# RN821X_RN721X_SOC_D register map
File version: v1.0.6
CPU: CM0 r0p0, little endian, no MPU, no FPU, 3 interrupt priority bits
Registers are 32-bit, read-write, reset 0x0 unless marked. A register's access mark holds for its fields unless they carry their own. Offsets are from the block's base; [hi:lo] are bit positions; {n}, {i} and the like mark numbered series; 'fields as' and 'values as' point back to an identical list.

## KBI — key detection
Base 0x40028000
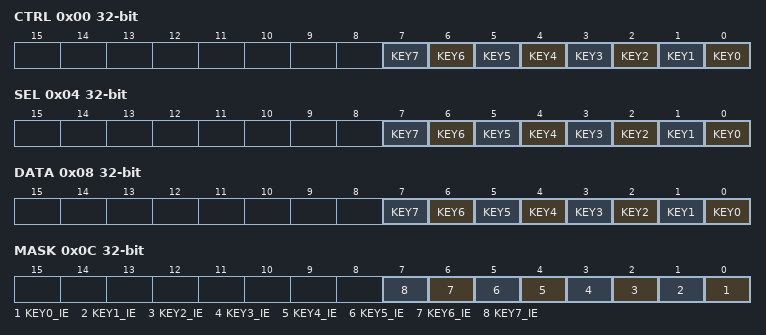
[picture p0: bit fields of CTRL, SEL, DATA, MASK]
0x00 CTRL — KBI control register
  [n] KEY{n} (n=0..7) — KBI KEY{n} enable/disable bit
    1=EN (KBI KEY{n} enable); 0=DIS (KBI KEY{n} disable)
0x04 SEL — KBI trigger mode select register
  [all] fields
    0=PE (KBI select posedge sampling); 1=NE (KBI select negedge sampling)
  [n] KEY{n} (n=0..7) — KBI KEY{n} posedge/negedge selection bit
0x08 DATA — KBI data register
  [all] fields
    1=PD (KEY pressed); 0=NUL (KEY not be pressed)
  [n] KEY{n} write-1-clears (n=0..7) — KBI KEY{n} data bit indicate key pressed or not
0x0C MASK — KBI interrupt mask register
  [n] KEY{n}_IE (n=0..7) — KBI KEY{n} interrupt enable/disable bit

## NVM — no voltage module
Base 0x40040000
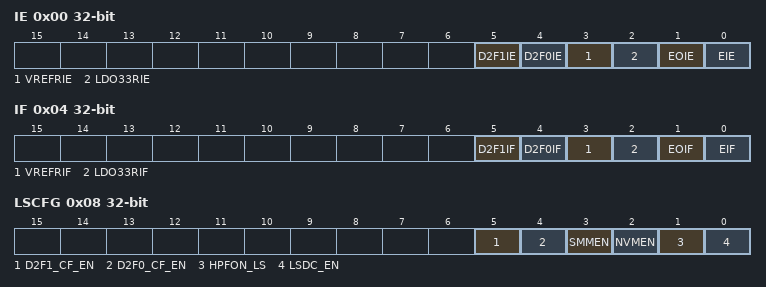
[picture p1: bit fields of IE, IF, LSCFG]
0x00 IE — interrupt enables
  [5] D2F1IE — d2f1 pulse interrupt enable
    0=DIS (do not generate interrupt when d2f1 pulse is output); 1=EN (generate interrupt when d2f1 pulse is output)
  [4] D2F0IE — d2f0 pulse interrupt enable
    0=DIS (do not generate interrupt when d2f0 pulse is output); 1=EN (generate interrupt when d2f0 pulse is output)
  [3] VREFRIE — VREF reset interrupt enable
    0=DIS (do not generate interrupt when VREF reset found); 1=EN (generate interrupt when VREF reset found)
  [2] LDO33RIE — LDO33 reset interrupt enable
    0=DIS (do not generate interrupt when reset found in LDO33 power domain); 1=EN (generate interrupt when reset found in LDO33 power domain)
  [1] EOIE — NV end and overflow interrupt enable
    0=DIS (do not generate interrupt when NV computation ends and NV value beyond threshold); 1=EN (generate interrupt when NV computation ends and NV value beyond threshold)
  [0] EIE — NV end interrupt enable
    0=DIS (do not generate interrupt when NV computation ends); 1=EN (generate interrupt when NV computation ends)
0x04 IF — interrupt flag
  [5] D2F1IF — d2f1 impulse interrupt flag
    0=NULL (no pending event of d2f1 impulse); 1=OCC (pending event of d2f1 impulse interrupt flag)
  [4] D2F0IF — d2f0 impulse interrupt flag
    0=NULL (no pending event of d2f0 impulse); 1=OCC (pending event of d2f0 impulse interrupt flag)
  [3] VREFRIF — VREF reset interrupt flag
    0=NULL (no pending event of VREF domain reset); 1=OCC (pending event of VREF domain reset found)
  [2] LDO33RIF — LDO33 reset interrupt flag
    0=NULL (no pending event of LDO33 power domain reset); 1=OCC (pending event of LDO33 power domain reset found)
  [1] EOIF — NV end and overflow interrupt flag
    0=NULL (no pending event of NV computation ends and NV value beyond threshold); 1=OCC (pending event of NV computation ends and NV value beyond threshold found)
  [0] EIF — NV end interrupt flag
    values as EOIF
0x08 LSCFG — NV config
  [5] D2F1_CF_EN — SMM enable
    0=DIS (D2F1 pulse not output to io); 1=EN (D2F1 pulse output to io)
  [4] D2F0_CF_EN — SMM enable
    0=DIS; 1=EN
  [3] SMMEN — SMM enable
    0=DIS (RMS updated every 20ms); 1=EN (RMS updated every 80ms)
  [2] NVMEN — module enable
    0=DIS (disabled); 1=EN (enabled)
  [1] HPFON_LS — high pass filter enable
    0=DIS (disabled); 1=EN (enabled)
  [0] LSDC_EN — automatic DC offset calibration enable
    0=DIS (disabled); 1=EN (enabled)
0x0C LSDCOS — NV measurement DC offset.
  [23:0] LSDCOS
0x10 LSTHO — NV measurement threshold
  [23:0] LSTHO
0x14 LSRMS ro — IA cyclic updated NV measurement RMS
  [23:0] LSRMS
0x18 LSRMS1 ro — IA RMS_L1 will not change after calculation
  [23:0] LSRMS1
0x20 HFCONST — HF const value
  [15:0] HFCONST
0x24 D2FP0 — D2F power 0 vaule
  [23:0] D2FP0
0x28 D2FP1 — D2F power 1 vaule
  [23:0] D2FP1

## SPI0 — synchronous peripheral interface
Base 0x40020000
Same registers: SPI1 0x40050000
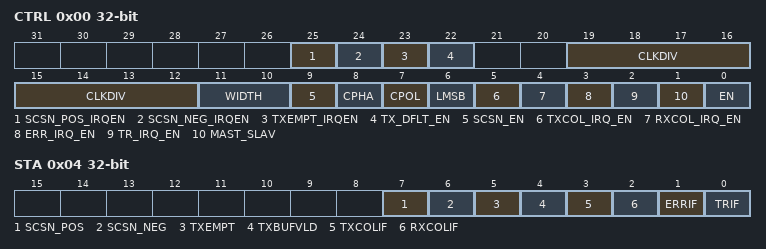
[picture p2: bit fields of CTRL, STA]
0x00 CTRL — SPI control register
  [25] SCSN_POS_IRQEN — CSN POS interrupt
  [24] SCSN_NEG_IRQEN — CSN NEG interrupt
  [23] TXEMPT_IRQEN — transmit empty interrupt
  [22] TX_DFLT_EN — transmit data when TX buffer empty
    1=DFLT (transmit SPI_TXDFLT reg data when transmit buffer empty); 0=LAST (transmit last time reg data of SPI_TXDATA when transmit buffer empty)
  [19:12] CLKDIV — clock divisor for SCK.frequency of SCK is (frequency of system clock)/(2*(CLKDIV+1))
  [11:10] WIDTH — data width selection
    0=8BIT (select data width as 8 bit); 1=16BIT (select data width as 16 bit); 2=32BIT (select data width as 32 bit)
  [9] SCSN_EN — SCSN error detection enable.applicable in master mode
  [8] CPHA — clock phase selection
    0=SAMP (leading edge sampling data, trailing edge build data); 1=BUILD (leading edge build data, trailing edge sampling data)
  [7] CPOL — clock polarity selection
    0=EL (select low level for 'SCK' empty status); 1=EH (select high level for 'SCK' empty status)
  [6] LMSB — LSB or MSB selection
    0=MSB (MSB transmitted first); 1=LSB (LSB transmitted first)
  [5] TXCOL_IRQ_EN — transmit data collision interrupt enable
  [4] RXCOL_IRQ_EN — receive data collision interrupt enable
  [3] ERR_IRQ_EN — SCSN error interrupt enable
  [2] TR_IRQ_EN — transmit interrupt enable
  [1] MAST_SLAV — master slave selection
    1=M (select as master device); 0=S (select as slave device)
  [0] EN — module enable
0x04 STA — SPI status register
  [7] SCSN_POS — CSN negedge flag
  [6] SCSN_NEG — CSN posedge flag
  [5] TXEMPT — transmit buffer empty conflict flag (buffer empty but need to transmit)
  [4] TXBUFVLD — transmit buffer not empty flag
  [3] TXCOLIF write-1-clears — transmit data overflow interrupt flag
  [2] RXCOLIF write-1-clears — receive data overflow interrupt flag
  [1] ERRIF write-1-clears — SCSN error interrupt flag
  [0] TRIF write-1-clears — transmit interrupt flag
0x08 TX — SPI transmit data register
  [31:0] TX — transmit data bits
0x0C RX ro — SPI receive data register
  [31:0] RX — receive data bits
0x10 TXDFLT — SPI tx default data register
  [31:0] TXDFLT — transmit default data bits

## UART0 — UART tranceiver
Base 0x40000000
Same registers: UART1 0x40004000, UART2 0x40008000, UART3 0x4000C000, UART4 0x40018000, UART5 0x4001C000
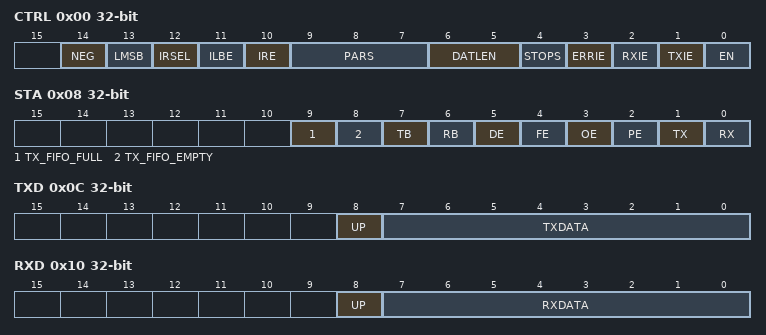
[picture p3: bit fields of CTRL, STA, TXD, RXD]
0x00 CTRL — UART control register
  [14] NEG — UART transfer polarity selection bit
    0=P (positive polarity (default driving voltage is high)); 1=N (negative polarity (default driving voltage is low))
  [13] LMSB — LSB/MSB transfer mode selection
    0=L (LSB first transfer mode); 1=M (MSB first transfer mode)
  [12] IRSEL — infra-red modulation polarity selection bit
    0=P (positive polarity. default driving voltage is high); 1=N (negative polarity. default driving voltage is low)
  [11] ILBE — inner loopback enable bit
  [10] IRE — infra-red modulation enable bit
  [9:7] PARS — parity type selection bits
    0=NUL (parity type select no parity); 1=ODD (parity type select odd parity); 2=EVEN (parity type select even parity); 3=parity type select stick_zero parity; 4=parity type select stick one parity; 5=USER (parity type select user_defined parity)
  [6:5] DATLEN — data length of frame format Configuration bits
    {v}=select {v+5} bits of data field (v=0..3)
  [4] STOPS — stop bits width selection bit
    1=2BIT (stop bit_width select as 2 bit); 0=1BIT (stop bit_width select as 1 bit)
  [3] ERRIE — error interrupt enable bit
  [2] RXIE — receive interrupt enable bit
  [1] TXIE — transmit interrupt enable bit
  [0] EN — UART module enable bit
0x04 BAUD — UART baud rate configuration register
  [11:0] CLKDIV — baud rate configuration bits
0x08 STA — UART status register
  [9] TX_FIFO_FULL — transmit fifo full flag
  [8] TX_FIFO_EMPTY — transmit fifo empty flag
  [7] TB — transmit busy flag
  [6] RB — receive busy flag
  [5] DE write-1-clears — data error flag
  [4] FE write-1-clears — frame error flag
  [3] OE write-1-clears — overflow error flag
  [2] PE write-1-clears — parity error flag
  [1] TX write-1-clears — transmit finish flag
  [0] RX write-1-clears — receive finish flag
0x0C TXD — UART transmit data register
  [8] UP — User-defined parity bit(valid when user-defined parity selected)
  [7:0] TXDATA — Transmit data value
0x10 RXD — UART receive data register
  [8] UP ro — user-defined parity bit(valid when user-defined parity selected)
  [7:0] RXDATA ro — Received data value bits
0x14 FDIV — baud rate fractional part
  [13:0] FDIV — baud rate fractional divisor configuration bits

## WDT — watchdog timer
Base 0x40030000
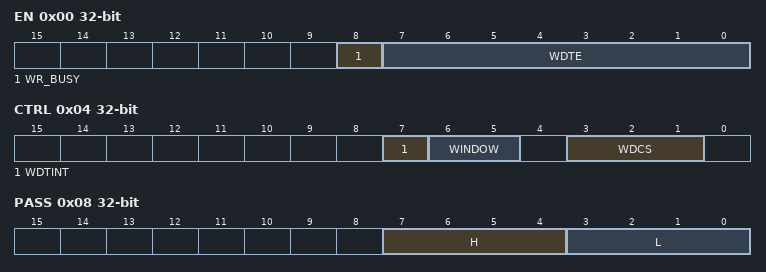
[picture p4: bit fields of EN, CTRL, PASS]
0x00 EN — Watchdog enable register
  [8] WR_BUSY ro — WDT write busy flag
  [7:0] WDTE — WDT enable bits
    187=RESTART (clear WDT counter and restart WDT(write value)); 85=DIS_DFLT (WDTE default value)
0x04 CTRL — WDT control register
  [7] WDTINT — WDT Timer Interval Interrupt
  [6:5] WINDOW — WDT Window Open Period
  [3:1] WDCS — WDT overflow time config
0x08 PASS — WDT password register
  [7:4] H ro — WDT high part password
  [3:0] L — WDT low part password
0x14 HALT — WDT HALT control register
  [15:0] EN — HALT_EN config bits
0x18 STBY — WDT STBY control register
  [15:0] EN — STBY_EN config bits
